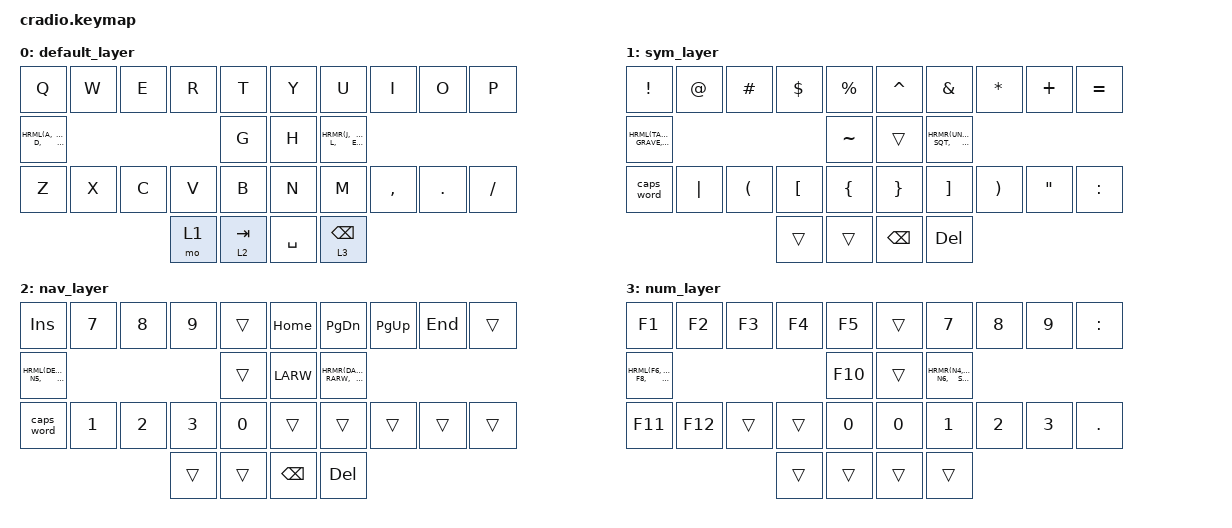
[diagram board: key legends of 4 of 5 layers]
// Copyright (c) 2022 The ZMK Contributors
// SPDX-License-Identifier: MIT

#include <behaviors.dtsi>
#include <dt-bindings/zmk/keys.h>
#include <dt-bindings/zmk/bt.h>

// Home row mods macro
#define HRML(k1,k2,k3,k4) &ht LALT  k1  &ht LGUI  k2  &ht LCTRL k3  &ht_s LSHFT k4
#define HRMR(k1,k2,k3,k4) &ht RSHFT k1  &ht RCTRL k2  &ht RGUI  k3  &ht RALT  k4

/ {
    behaviors {
        // Shorter tapping term to prefer the shifted version at high speed
        ht_s: hold_tap_shift {
            compatible = "zmk,behavior-hold-tap";
            #binding-cells = <2>;
            flavor = "tap-preferred";
            tapping-term-ms = <180>;
            quick-tap-ms = <200>;
            require-prior-idle-ms = <100>;
            bindings = <&kp>, <&kp>;
        };
        // Long tapping term to really avoid tapping by accident
        ht: hold_others {
            compatible = "zmk,behavior-hold-tap";
            #binding-cells = <2>;
            flavor = "tap-preferred";
            tapping-term-ms = <280>;
            quick-tap-ms = <200>;
            require-prior-idle-ms = <100>;
            bindings = <&kp>, <&kp>;
        };
    };

    conditional_layers {
        compatible = "zmk,conditional-layers";
        tri_layer {
            if-layers = <1 2>;
            then-layer = <4>;
        };
    };

    keymap {
        compatible = "zmk,keymap";
        default_layer {
            bindings = <
        //╭──────────┬──────────┬──────────┬──────────┬──────────╮   ╭──────────┬──────────┬──────────┬──────────┬──────────╮
        //│  Q       │  W       │  E       │  R       │  T       │   │  Y       │  U       │  I       │  O       │  P       │
            &kp Q      &kp W      &kp E      &kp R      &kp T          &kp Y      &kp U      &kp I      &kp O      &kp P
        //├──────────┼──────────┼──────────┼──────────┼──────────┤   ├──────────┼──────────┼──────────┼──────────┼──────────┤
        //│  A       │  S       │  D       │  F       │  G       │   │  H       │  J       │  K       │  L       │          │
            HRML(A,        S,         D,         F)     &kp G          &kp H      HRMR(J,        K,         L,        ENTER)
        //├──────────┼──────────┼──────────┼──────────┼──────────┤   ├──────────┼──────────┼──────────┼──────────┼──────────┤
        //│  Z       │  X       │  C       │  V       │  B       │   │  N       │  M       │ , <      │ . >      │ / ?      │
            &kp Z      &kp X      &kp C      &kp V      &kp B          &kp N      &kp M      &kp COMMA  &kp DOT    &kp FSLH
        //╰──────────┴──────────┴──────────┼──────────┼──────────┤   ├──────────┼──────────┼──────────┴──────────┴──────────╯
                                            &mo 1      &lt 2 TAB      &kp SPACE  &lt 3 BSPC
        //                                 ╰──────────┴──────────╯   ╰──────────┴──────────╯
            >;
        };

        sym_layer {
            bindings = <
        //╭──────────┬──────────┬──────────┬──────────┬──────────╮   ╭──────────┬──────────┬──────────┬──────────┬──────────╮
        //│  !       │  @       │  #       │  $       │  %       │   │  ^       │  &       │  *       │  +       │  =       │
            &kp EXCL   &kp AT     &kp HASH   &kp DLLR   &kp PRCNT      &kp CARET  &kp AMPS  &kp ASTRK  &kp PLUS   &kp EQUAL
        //├──────────┼──────────┼──────────┼──────────┼──────────┤   ├──────────┼──────────┼──────────┼──────────┼──────────┤
        //│ TAB      │  \       │  `       │  ESC     │  ~       │   │          │  _       │  -       │  '       │  ;       │
            HRML(TAB,   BSLH,      GRAVE,    ESC)      &kp TILDE       &trans    HRMR(UNDER,  MINUS,     SQT,       SEMI)
        //├──────────┼──────────┼──────────┼──────────┼──────────┤   ├──────────┼──────────┼──────────┼──────────┼──────────┤
        //│ CAPS     │  |       │  (       │  [       │  {       │   │  }       │  ]       │  )       │  "       │  :       │
           &caps_word  &kp PIPE   &kp LPAR   &kp LBKT   &kp LBRC       &kp RBRC   &kp RBKT   &kp RPAR   &kp DQT  &kp COLON
        //╰──────────┴──────────┴──────────┼──────────┼──────────┤   ├──────────┼──────────┼──────────┴──────────┴──────────╯
                                             &trans      &trans         &kp BSPC   &kp DEL
        //                                 ╰──────────┴──────────╯   ╰──────────┴──────────╯
            >;
        };

        nav_layer {
            bindings = <
        //╭──────────┬──────────┬──────────┬──────────┬──────────╮   ╭──────────┬──────────┬──────────┬──────────┬──────────╮
        //│ INSERT   │  7       │  8       │  9       │          │   │ HOME     │ PAGE DN  │ PAGE UP  │ END      │  :       │
            &kp INS    &kp N7     &kp N8     &kp N9     &trans         &kp HOME   &kp PG_DN  &kp PG_UP  &kp END    &trans
        //├──────────┼──────────┼──────────┼──────────┼──────────┤   ├──────────┼──────────┼──────────┼──────────┼──────────┤
        //│ DELETE   │  4       │  5       │  6       │          │   │ LEFT     │ DOWN     │ UP       │ RIGHT    │  ;       │
            HRML(DEL,   N4,        N5,        N6)       &trans         &kp LARW   HRMR(DARW, UARW,      RARW,      SEMI)
        //├──────────┼──────────┼──────────┼──────────┼──────────┤   ├──────────┼──────────┼──────────┼──────────┼──────────┤
        //│ CAPS     │  1       │  2       │  3       │  0       │   │          │          │          │          │          │
           &caps_word  &kp N1     &kp N2     &kp N3     &kp N0         &trans     &trans     &trans     &trans     &trans
        //╰──────────┴──────────┴──────────┼──────────┼──────────┤   ├──────────┼──────────┼──────────┴──────────┴──────────╯
                                             &trans     &trans         &kp BSPC   &kp DEL
        //                                 ╰──────────┴──────────╯   ╰──────────┴──────────╯
            >;
        };
        num_layer {
            bindings = <
        //╭──────────┬──────────┬──────────┬──────────┬──────────╮   ╭──────────┬──────────┬──────────┬──────────┬──────────╮
        //│          │          │          │          │          │   │          │  7       │  8       │  9       │  :       │
            &kp F1     &kp F2     &kp F3     &kp F4     &kp F5         &trans      &kp N7     &kp N8     &kp N9     &kp COLON
        //├──────────┼──────────┼──────────┼──────────┼──────────┤   ├──────────┼──────────┼──────────┼──────────┼──────────┤
        //│          │          │          │          │          │   │          │ 4        │  5       │  6       │  ;       │
            HRML(F6,     F7,       F8,        F9)      &kp F10        &trans      HRMR(N4,    N5,        N6,     SEMI)
        //├──────────┼──────────┼──────────┼──────────┼──────────┤   ├──────────┼──────────┼──────────┼──────────┼──────────┤
        //│          │          │          │          │  0       │   │  0       │  1       │  2       │  3       │  .       │
           &kp F11     &kp F12    &trans    &trans      &kp N0         &kp N0      &kp N1     &kp N2     &kp N3     &kp DOT
        //╰──────────┴──────────┴──────────┼──────────┼──────────┤   ├──────────┼──────────┴──────────┼──────────┼──────────╯
                                             &trans     &trans         &trans     &trans
        //                                 ╰──────────┴──────────╯   ╰──────────┴──────────╯
            >;
        };


        tri_layer {
            bindings = <
        //╭──────────┬──────────┬──────────┬──────────┬──────────╮   ╭──────────┬──────────┬──────────┬──────────┬──────────╮
        //│ RESET    │          │          │          │PROFILE 0 │   │          │          │          │          │  RESET   │
           &sys_reset  &trans     &trans     &trans    &bt BT_SEL 0    &trans     &trans     &trans     &trans    &sys_reset
        //├──────────┼──────────┼──────────┼──────────┼──────────┤   ├──────────┼──────────┼──────────┼──────────┼──────────┤
        //│BOOTLOADER│          │          │          │PROFILE 1 │   │          │          │          │          │BOOTLOADER│
          &bootloader  &trans     &trans     &trans    &bt BT_SEL 1    &trans     &trans     &trans     &trans    &bootloader
        //├──────────┼──────────┼──────────┼──────────┼──────────┤   ├──────────┼──────────┼──────────┼──────────┼──────────┤
        //│          │          │          │ CLEAR BT │PROFILE 2 │   │          │          │          │          │          │
            &trans     &trans     &trans    &bt BT_CLR &bt BT_SEL 2    &trans     &trans     &trans     &trans     &trans
        //╰──────────┴──────────┴──────────┼──────────┼──────────┤   ├──────────┼──────────┼──────────┴──────────┴──────────╯
                                             &trans     &trans         &trans     &trans
        //                                 ╰──────────┴──────────╯   ╰──────────┴──────────╯
            >;
        };
    };
};
